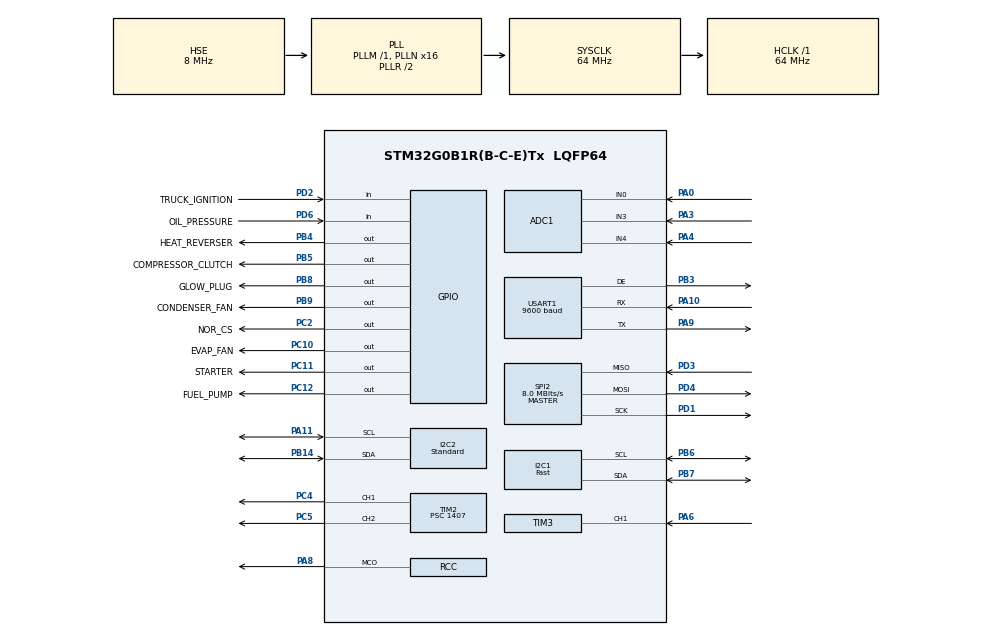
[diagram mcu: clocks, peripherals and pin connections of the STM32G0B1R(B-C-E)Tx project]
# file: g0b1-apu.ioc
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ADC1.ClockPrescaler=ADC_CLOCK_SYNC_PCLK_DIV4
ADC1.ContinuousConvMode=ENABLE
ADC1.DMAContinuousRequests=ENABLE
ADC1.NbrOfConversion=1
ADC1.NbrOfConversionFlag=0
ADC1.Overrun=ADC_OVR_DATA_OVERWRITTEN
ADC1.OversamplingMode=ENABLE
ADC1.Ratio=ADC_OVERSAMPLING_RATIO_16
ADC1.RightBitShift=ADC_RIGHTBITSHIFT_4
ADC1.SamplingTimeCommon1=ADC_SAMPLETIME_160CYCLES_5
ADC1.SelectedChannel=ADC_CHANNEL_0|ADC_CHANNEL_3|ADC_CHANNEL_4
ADC1.Sequencer=NOT_FULLY_CONFIGURABLE
ADC1.master=1
Dma.ADC1.2.Direction=DMA_PERIPH_TO_MEMORY
Dma.ADC1.2.EventEnable=DISABLE
Dma.ADC1.2.Instance=DMA1_Channel3
Dma.ADC1.2.MemDataAlignment=DMA_MDATAALIGN_HALFWORD
Dma.ADC1.2.MemInc=DMA_MINC_ENABLE
Dma.ADC1.2.Mode=DMA_CIRCULAR
Dma.ADC1.2.PeriphDataAlignment=DMA_PDATAALIGN_HALFWORD
Dma.ADC1.2.PeriphInc=DMA_PINC_DISABLE
Dma.ADC1.2.Polarity=HAL_DMAMUX_REQ_GEN_RISING
Dma.ADC1.2.Priority=DMA_PRIORITY_LOW
Dma.ADC1.2.RequestNumber=1
Dma.ADC1.2.SignalID=NONE
Dma.ADC1.2.SyncEnable=DISABLE
Dma.ADC1.2.SyncPolarity=HAL_DMAMUX_SYNC_NO_EVENT
Dma.ADC1.2.SyncRequestNumber=1
Dma.ADC1.2.SyncSignalID=NONE
Dma.Request0=USART1_RX
Dma.Request1=USART1_TX
Dma.Request2=ADC1
Dma.USART1_RX.0.Direction=DMA_PERIPH_TO_MEMORY
Dma.USART1_RX.0.EventEnable=DISABLE
Dma.USART1_RX.0.Instance=DMA1_Channel1
Dma.USART1_RX.0.MemDataAlignment=DMA_MDATAALIGN_BYTE
Dma.USART1_RX.0.MemInc=DMA_MINC_ENABLE
Dma.USART1_RX.0.Mode=DMA_NORMAL
Dma.USART1_RX.0.PeriphDataAlignment=DMA_PDATAALIGN_BYTE
Dma.USART1_RX.0.PeriphInc=DMA_PINC_DISABLE
Dma.USART1_RX.0.Polarity=HAL_DMAMUX_REQ_GEN_RISING
Dma.USART1_RX.0.Priority=DMA_PRIORITY_LOW
Dma.USART1_RX.0.RequestNumber=1
Dma.USART1_RX.0.SignalID=NONE
Dma.USART1_RX.0.SyncEnable=DISABLE
Dma.USART1_RX.0.SyncPolarity=HAL_DMAMUX_SYNC_NO_EVENT
Dma.USART1_RX.0.SyncRequestNumber=1
Dma.USART1_RX.0.SyncSignalID=NONE
Dma.USART1_TX.1.Direction=DMA_MEMORY_TO_PERIPH
Dma.USART1_TX.1.EventEnable=DISABLE
Dma.USART1_TX.1.Instance=DMA1_Channel2
Dma.USART1_TX.1.MemDataAlignment=DMA_MDATAALIGN_BYTE
Dma.USART1_TX.1.MemInc=DMA_MINC_ENABLE
Dma.USART1_TX.1.Mode=DMA_NORMAL
Dma.USART1_TX.1.PeriphDataAlignment=DMA_PDATAALIGN_BYTE
Dma.USART1_TX.1.PeriphInc=DMA_PINC_DISABLE
Dma.USART1_TX.1.Polarity=HAL_DMAMUX_REQ_GEN_RISING
Dma.USART1_TX.1.Priority=DMA_PRIORITY_LOW
Dma.USART1_TX.1.RequestNumber=1
Dma.USART1_TX.1.SignalID=NONE
Dma.USART1_TX.1.SyncEnable=DISABLE
Dma.USART1_TX.1.SyncPolarity=HAL_DMAMUX_SYNC_NO_EVENT
Dma.USART1_TX.1.SyncRequestNumber=1
Dma.USART1_TX.1.SyncSignalID=NONE
I2C1.AddressingMode=I2C_ADDRESSINGMODE_7BIT
I2C1.Analog_Filter=I2C_ANALOGFILTER_ENABLE
I2C1.CustomTiming=Disabled
I2C1.DualAddressMode=I2C_DUALADDRESS_DISABLE
I2C1.GeneralCallMode=I2C_GENERALCALL_DISABLE
I2C1.I2C_Coeff_DF=0x0
I2C1.I2C_Fall_Time=10
I2C1.I2C_Rise_Time=100
I2C1.I2C_Speed_Mode=I2C_Fast
I2C1.NoStretchMode=I2C_NOSTRETCH_DISABLE
I2C1.OwnAddress=0x0
I2C1.Speed=400
I2C1.Timing=0x00C0216C
I2C2.AddressingMode=I2C_ADDRESSINGMODE_7BIT
I2C2.Analog_Filter=I2C_ANALOGFILTER_ENABLE
I2C2.CustomTiming=Disabled
I2C2.DualAddressMode=I2C_DUALADDRESS_DISABLE
I2C2.GeneralCallMode=I2C_GENERALCALL_DISABLE
I2C2.I2C_Coeff_DF=0x0
I2C2.I2C_Fall_Time=10
I2C2.I2C_Rise_Time=100
I2C2.I2C_Speed_Mode=I2C_Standard
I2C2.NoStretchMode=I2C_NOSTRETCH_DISABLE
I2C2.OwnAddress=0x0
I2C2.Speed=50
I2C2.Timing=0xF0102527
IWDG.Prescaler=IWDG_PRESCALER_32
IWDG.Reload=1999
Mcu.Family=STM32G0
Mcu.Name=STM32G0B1R(B-C-E)Tx
Mcu.Package=LQFP64
NVIC.DMA1_Channel1_IRQn=true\:0\:0\:false\:false\:true\:false\:true\:true
NVIC.DMA1_Channel2_3_IRQn=true\:0\:0\:false\:false\:true\:false\:true\:true
NVIC.TIM3_TIM4_IRQn=true\:0\:0\:false\:false\:true\:true\:true\:true
NVIC.USART1_IRQn=true\:0\:0\:false\:false\:true\:true\:true\:true
PA0.Mode=IN0
PA0.Signal=ADC1_IN0
PA10.Mode=Asynchronous
PA10.Signal=USART1_RX
PA11\ [PA9].Mode=I2C
PA11\ [PA9].Signal=I2C2_SCL
PA13.Mode=Serial_Wire
PA13.Signal=SYS_SWDIO
PA14-BOOT0.Mode=Serial_Wire
PA14-BOOT0.Signal=SYS_SWCLK
PA3.Mode=IN3
PA3.Signal=ADC1_IN3
PA4.Mode=IN4
PA4.Signal=ADC1_IN4
PA6.Signal=S_TIM3_CH1
PA8.Mode=Clock-out
PA8.Signal=RCC_MCO
PA9.Mode=Asynchronous
PA9.Signal=USART1_TX
PB14.Mode=I2C
PB14.Signal=I2C2_SDA
PB3.Mode=Hardware Flow Control (RS485)
PB3.Signal=USART1_DE
PB4.GPIO_Label=HEAT_REVERSER
PB4.Signal=GPIO_Output
PB5.GPIO_Label=COMPRESSOR_CLUTCH
PB5.Signal=GPIO_Output
PB6.Mode=I2C
PB6.Signal=I2C1_SCL
PB7.Mode=I2C
PB7.Signal=I2C1_SDA
PB8.GPIO_Label=GLOW_PLUG
PB8.Signal=GPIO_Output
PB9.GPIO_Label=CONDENSER_FAN
PB9.Signal=GPIO_Output
PC10.GPIO_Label=EVAP_FAN
PC10.Signal=GPIO_Output
PC11.GPIO_Label=STARTER
PC11.Signal=GPIO_Output
PC12.GPIO_Label=FUEL_PUMP
PC12.Signal=GPIO_Output
PC2.GPIO_Label=NOR_CS
PC2.PinState=GPIO_PIN_SET
PC2.Signal=GPIO_Output
PC4.Signal=S_TIM2_CH1_ETR
PC5.Signal=S_TIM2_CH2
PD1.Mode=Full_Duplex_Master
PD1.Signal=SPI2_SCK
PD2.GPIO_Label=TRUCK_IGNITION
PD2.GPIO_PuPd=GPIO_PULLUP
PD2.Signal=GPIO_Input
PD3.Mode=Full_Duplex_Master
PD3.Signal=SPI2_MISO
PD4.Mode=Full_Duplex_Master
PD4.Signal=SPI2_MOSI
PD6.GPIO_Label=OIL_PRESSURE
PD6.GPIO_PuPd=GPIO_PULLUP
PD6.Signal=GPIO_Input
PF0-OSC_IN\ (PF0).Mode=HSE-External-Oscillator
PF0-OSC_IN\ (PF0).Signal=RCC_OSC_IN
PF1-OSC_OUT\ (PF1).Mode=HSE-External-Oscillator
PF1-OSC_OUT\ (PF1).Signal=RCC_OSC_OUT
ProjectManager.HeapSize=0x200
ProjectManager.StackSize=0x400
ProjectManager.TargetToolchain=STM32CubeIDE
RCC.ADCFreq_Value=64000000
RCC.AHBFreq_Value=64000000
RCC.CortexFreq_Value=64000000
RCC.EXTERNAL_CLOCK_VALUE=48000
RCC.HCLKFreq_Value=64000000
RCC.HSE_VALUE=8000000
RCC.HSI48_VALUE=48000000
RCC.HSI_VALUE=16000000
RCC.LSE_VALUE=32768
RCC.PLLN=16
RCC.PLLP=RCC_PLLP_DIV4
RCC.PLLSourceVirtual=RCC_PLLSOURCE_HSE
RCC.RCC_MCODiv=RCC_MCODIV_16
RCC.SYSCLKFreq_VALUE=64000000
RCC.SYSCLKSource=RCC_SYSCLKSOURCE_PLLCLK
RCC.USBFreq_Value=48000000
RCC.VCOOutputFreq_Value=128000000
SH.S_TIM2_CH1_ETR.0=TIM2_CH1,PWM Generation1 CH1
SH.S_TIM2_CH2.0=TIM2_CH2,PWM Generation2 CH2
SH.S_TIM3_CH1.0=TIM3_CH1,Input_Capture1_from_TI1
SPI2.BaudRatePrescaler=SPI_BAUDRATEPRESCALER_8
SPI2.CLKPhase=SPI_PHASE_1EDGE
SPI2.CLKPolarity=SPI_POLARITY_LOW
SPI2.CalculateBaudRate=8.0 MBits/s
SPI2.DataSize=SPI_DATASIZE_8BIT
SPI2.Direction=SPI_DIRECTION_2LINES
SPI2.FirstBit=SPI_FIRSTBIT_MSB
SPI2.Mode=SPI_MODE_MASTER
SPI2.NSS=SPI_NSS_SOFT
SPI2.VirtualType=VM_MASTER
TIM2.AutoReloadPreload=TIM_AUTORELOAD_PRELOAD_ENABLE
TIM2.Channel-PWM\ Generation1\ CH1=TIM_CHANNEL_1
TIM2.Channel-PWM\ Generation2\ CH2=TIM_CHANNEL_2
TIM2.Period=999
TIM2.Prescaler=1407
TIM2.Pulse-PWM\ Generation1\ CH1=0
TIM2.Pulse-PWM\ Generation2\ CH2=0
TIM3.Channel-Input_Capture1_from_TI1=TIM_CHANNEL_1
TIM3.ICFilter_CH1=12
TIM3.Prescaler=127
USART1.BaudRate=9600
USART1.VirtualMode-Asynchronous=VM_ASYNC
USART1.VirtualMode-Hardware\ Flow\ Control\ (RS485)=VM_ASYNC
VP_IWDG_VS_IWDG.Mode=IWDG_Activate
VP_SYS_VS_DBSignals.Mode=DisableDeadBatterySignals
VP_TIM3_VS_ClockSourceINT.Mode=Internal
board=custom

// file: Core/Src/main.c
/* USER CODE BEGIN Header */
/**
  ******************************************************************************
  * @file           : main.c
  * @brief          : Main program body
  ******************************************************************************
  * @attention
  *
  * Copyright (c) 2026 STMicroelectronics.
  * All rights reserved.
  *
  * This software is licensed under terms that can be found in the LICENSE file
  * in the root directory of this software component.
  * If no LICENSE file comes with this software, it is provided AS-IS.
  *
  ******************************************************************************
  */
/* USER CODE END Header */
#include "main.h"

/* USER CODE BEGIN Includes */
#include "app_main.h"
/* USER CODE END Includes */

ADC_HandleTypeDef hadc1;
DMA_HandleTypeDef hdma_adc1;

I2C_HandleTypeDef hi2c1;
I2C_HandleTypeDef hi2c2;

IWDG_HandleTypeDef hiwdg;

SPI_HandleTypeDef hspi2;

TIM_HandleTypeDef htim2;
TIM_HandleTypeDef htim3;

UART_HandleTypeDef huart1;
DMA_HandleTypeDef hdma_usart1_rx;
DMA_HandleTypeDef hdma_usart1_tx;

void SystemClock_Config(void);
static void MX_GPIO_Init(void);
static void MX_DMA_Init(void);
static void MX_TIM2_Init(void);
static void MX_USART1_UART_Init(void);
static void MX_SPI2_Init(void);
static void MX_I2C1_Init(void);
static void MX_ADC1_Init(void);
static void MX_TIM3_Init(void);
static void MX_I2C2_Init(void);
static void MX_IWDG_Init(void);

int main(void)
{

  /* MCU Configuration--------------------------------------------------------*/

  /* Reset of all peripherals, Initializes the Flash interface and the Systick. */
  HAL_Init();

  /* Configure the system clock */
  SystemClock_Config();

  /* Initialize all configured peripherals */
  MX_GPIO_Init();
  MX_DMA_Init();
  MX_TIM2_Init();
  MX_USART1_UART_Init();
  MX_SPI2_Init();
  MX_I2C1_Init();
  MX_ADC1_Init();
  MX_TIM3_Init();
  MX_I2C2_Init();
  MX_IWDG_Init();
  /* USER CODE BEGIN 2 */
  app_main();   /* never returns — owns the superloop (Task 1: idle; MCO on PA8 = 4 MHz validates the clock) */
  /* USER CODE END 2 */

  /* Infinite loop */
  while (1)
  {

  }
}

void SystemClock_Config(void)
{
  RCC_OscInitTypeDef RCC_OscInitStruct = {0};
  RCC_ClkInitTypeDef RCC_ClkInitStruct = {0};

  /** Configure the main internal regulator output voltage
  */
  HAL_PWREx_ControlVoltageScaling(PWR_REGULATOR_VOLTAGE_SCALE1);

  /** Initializes the RCC Oscillators according to the specified parameters
  * in the RCC_OscInitTypeDef structure.
  */
  RCC_OscInitStruct.OscillatorType = RCC_OSCILLATORTYPE_LSI|RCC_OSCILLATORTYPE_HSE;
  RCC_OscInitStruct.HSEState = RCC_HSE_ON;
  RCC_OscInitStruct.LSIState = RCC_LSI_ON;
  RCC_OscInitStruct.PLL.PLLState = RCC_PLL_ON;
  RCC_OscInitStruct.PLL.PLLSource = RCC_PLLSOURCE_HSE;
  RCC_OscInitStruct.PLL.PLLM = RCC_PLLM_DIV1;
  RCC_OscInitStruct.PLL.PLLN = 16;
  RCC_OscInitStruct.PLL.PLLP = RCC_PLLP_DIV4;
  RCC_OscInitStruct.PLL.PLLQ = RCC_PLLQ_DIV2;
  RCC_OscInitStruct.PLL.PLLR = RCC_PLLR_DIV2;
  if (HAL_RCC_OscConfig(&RCC_OscInitStruct) != HAL_OK)
  {
    Error_Handler();
  }

  /** Initializes the CPU, AHB and APB buses clocks
  */
  RCC_ClkInitStruct.ClockType = RCC_CLOCKTYPE_HCLK|RCC_CLOCKTYPE_SYSCLK
                              |RCC_CLOCKTYPE_PCLK1;
  RCC_ClkInitStruct.SYSCLKSource = RCC_SYSCLKSOURCE_PLLCLK;
  RCC_ClkInitStruct.AHBCLKDivider = RCC_SYSCLK_DIV1;
  RCC_ClkInitStruct.APB1CLKDivider = RCC_HCLK_DIV1;

  if (HAL_RCC_ClockConfig(&RCC_ClkInitStruct, FLASH_LATENCY_2) != HAL_OK)
  {
    Error_Handler();
  }
  HAL_RCC_MCOConfig(RCC_MCO1, RCC_MCO1SOURCE_SYSCLK, RCC_MCODIV_16);
}

static void MX_ADC1_Init(void)
{

  ADC_ChannelConfTypeDef sConfig = {0};

  /** Configure the global features of the ADC (Clock, Resolution, Data Alignment and number of conversion)
  */
  hadc1.Instance = ADC1;
  hadc1.Init.ClockPrescaler = ADC_CLOCK_SYNC_PCLK_DIV4;
  hadc1.Init.Resolution = ADC_RESOLUTION_12B;
  hadc1.Init.DataAlign = ADC_DATAALIGN_RIGHT;
  hadc1.Init.ScanConvMode = ADC_SCAN_SEQ_FIXED;
  hadc1.Init.EOCSelection = ADC_EOC_SINGLE_CONV;
  hadc1.Init.LowPowerAutoWait = DISABLE;
  hadc1.Init.LowPowerAutoPowerOff = DISABLE;
  hadc1.Init.ContinuousConvMode = ENABLE;
  hadc1.Init.NbrOfConversion = 1;
  hadc1.Init.ExternalTrigConv = ADC_SOFTWARE_START;
  hadc1.Init.ExternalTrigConvEdge = ADC_EXTERNALTRIGCONVEDGE_NONE;
  hadc1.Init.DMAContinuousRequests = ENABLE;
  hadc1.Init.Overrun = ADC_OVR_DATA_OVERWRITTEN;
  hadc1.Init.SamplingTimeCommon1 = ADC_SAMPLETIME_160CYCLES_5;
  hadc1.Init.OversamplingMode = ENABLE;
  hadc1.Init.Oversampling.Ratio = ADC_OVERSAMPLING_RATIO_16;
  hadc1.Init.Oversampling.RightBitShift = ADC_RIGHTBITSHIFT_4;
  hadc1.Init.Oversampling.TriggeredMode = ADC_TRIGGEREDMODE_SINGLE_TRIGGER;
  hadc1.Init.TriggerFrequencyMode = ADC_TRIGGER_FREQ_HIGH;
  if (HAL_ADC_Init(&hadc1) != HAL_OK)
  {
    Error_Handler();
  }

  /** Configure Regular Channel
  */
  sConfig.Channel = ADC_CHANNEL_0;
  sConfig.Rank = ADC_RANK_CHANNEL_NUMBER;
  if (HAL_ADC_ConfigChannel(&hadc1, &sConfig) != HAL_OK)
  {
    Error_Handler();
  }

  /** Configure Regular Channel
  */
  sConfig.Channel = ADC_CHANNEL_3;
  if (HAL_ADC_ConfigChannel(&hadc1, &sConfig) != HAL_OK)
  {
    Error_Handler();
  }

  /** Configure Regular Channel
  */
  sConfig.Channel = ADC_CHANNEL_4;
  if (HAL_ADC_ConfigChannel(&hadc1, &sConfig) != HAL_OK)
  {
    Error_Handler();
  }

}

static void MX_I2C1_Init(void)
{

  hi2c1.Instance = I2C1;
  hi2c1.Init.Timing = 0x00C0216C;
  hi2c1.Init.OwnAddress1 = 0;
  hi2c1.Init.AddressingMode = I2C_ADDRESSINGMODE_7BIT;
  hi2c1.Init.DualAddressMode = I2C_DUALADDRESS_DISABLE;
  hi2c1.Init.OwnAddress2 = 0;
  hi2c1.Init.OwnAddress2Masks = I2C_OA2_NOMASK;
  hi2c1.Init.GeneralCallMode = I2C_GENERALCALL_DISABLE;
  hi2c1.Init.NoStretchMode = I2C_NOSTRETCH_DISABLE;
  if (HAL_I2C_Init(&hi2c1) != HAL_OK)
  {
    Error_Handler();
  }

  /** Configure Analogue filter
  */
  if (HAL_I2CEx_ConfigAnalogFilter(&hi2c1, I2C_ANALOGFILTER_ENABLE) != HAL_OK)
  {
    Error_Handler();
  }

  /** Configure Digital filter
  */
  if (HAL_I2CEx_ConfigDigitalFilter(&hi2c1, 0x0) != HAL_OK)
  {
    Error_Handler();
  }

}

static void MX_I2C2_Init(void)
{

  hi2c2.Instance = I2C2;
  hi2c2.Init.Timing = 0x60302730; /* 100 kHz standard mode at 64 MHz PCLK */
  hi2c2.Init.OwnAddress1 = 0;
  hi2c2.Init.AddressingMode = I2C_ADDRESSINGMODE_7BIT;
  hi2c2.Init.DualAddressMode = I2C_DUALADDRESS_DISABLE;
  hi2c2.Init.OwnAddress2 = 0;
  hi2c2.Init.OwnAddress2Masks = I2C_OA2_NOMASK;
  hi2c2.Init.GeneralCallMode = I2C_GENERALCALL_DISABLE;
  hi2c2.Init.NoStretchMode = I2C_NOSTRETCH_DISABLE;
  if (HAL_I2C_Init(&hi2c2) != HAL_OK)
  {
    Error_Handler();
  }

  /** Configure Analogue filter
  */
  if (HAL_I2CEx_ConfigAnalogFilter(&hi2c2, I2C_ANALOGFILTER_ENABLE) != HAL_OK)
  {
    Error_Handler();
  }

  /** Configure Digital filter
  */
  if (HAL_I2CEx_ConfigDigitalFilter(&hi2c2, 0x0) != HAL_OK)
  {
    Error_Handler();
  }

}

static void MX_IWDG_Init(void)
{

  hiwdg.Instance = IWDG;
  hiwdg.Init.Prescaler = IWDG_PRESCALER_32;
  hiwdg.Init.Window = 4095;
  hiwdg.Init.Reload = 1999;
  if (HAL_IWDG_Init(&hiwdg) != HAL_OK)
  {
    Error_Handler();
  }

}

static void MX_SPI2_Init(void)
{

  /* SPI2 parameter configuration*/
  hspi2.Instance = SPI2;
  hspi2.Init.Mode = SPI_MODE_MASTER;
  hspi2.Init.Direction = SPI_DIRECTION_2LINES;
  hspi2.Init.DataSize = SPI_DATASIZE_8BIT;
  hspi2.Init.CLKPolarity = SPI_POLARITY_LOW;
  hspi2.Init.CLKPhase = SPI_PHASE_1EDGE;
  hspi2.Init.NSS = SPI_NSS_SOFT;
  hspi2.Init.BaudRatePrescaler = SPI_BAUDRATEPRESCALER_8;
  hspi2.Init.FirstBit = SPI_FIRSTBIT_MSB;
  hspi2.Init.TIMode = SPI_TIMODE_DISABLE;
  hspi2.Init.CRCCalculation = SPI_CRCCALCULATION_DISABLE;
  hspi2.Init.CRCPolynomial = 7;
  hspi2.Init.CRCLength = SPI_CRC_LENGTH_DATASIZE;
  hspi2.Init.NSSPMode = SPI_NSS_PULSE_ENABLE;
  if (HAL_SPI_Init(&hspi2) != HAL_OK)
  {
    Error_Handler();
  }

}

static void MX_TIM2_Init(void)
{

  TIM_MasterConfigTypeDef sMasterConfig = {0};
  TIM_OC_InitTypeDef sConfigOC = {0};

  htim2.Instance = TIM2;
  htim2.Init.Prescaler = 1407;
  htim2.Init.CounterMode = TIM_COUNTERMODE_UP;
  htim2.Init.Period = 999;
  htim2.Init.ClockDivision = TIM_CLOCKDIVISION_DIV1;
  htim2.Init.AutoReloadPreload = TIM_AUTORELOAD_PRELOAD_ENABLE;
  if (HAL_TIM_PWM_Init(&htim2) != HAL_OK)
  {
    Error_Handler();
  }
  sMasterConfig.MasterOutputTrigger = TIM_TRGO_RESET;
  sMasterConfig.MasterSlaveMode = TIM_MASTERSLAVEMODE_DISABLE;
  if (HAL_TIMEx_MasterConfigSynchronization(&htim2, &sMasterConfig) != HAL_OK)
  {
    Error_Handler();
  }
  sConfigOC.OCMode = TIM_OCMODE_PWM1;
  sConfigOC.Pulse = 0;
  sConfigOC.OCPolarity = TIM_OCPOLARITY_HIGH;
  sConfigOC.OCFastMode = TIM_OCFAST_DISABLE;
  if (HAL_TIM_PWM_ConfigChannel(&htim2, &sConfigOC, TIM_CHANNEL_1) != HAL_OK)
  {
    Error_Handler();
  }
  if (HAL_TIM_PWM_ConfigChannel(&htim2, &sConfigOC, TIM_CHANNEL_2) != HAL_OK)
  {
    Error_Handler();
  }
  HAL_TIM_MspPostInit(&htim2);

}

static void MX_TIM3_Init(void)
{

  TIM_ClockConfigTypeDef sClockSourceConfig = {0};
  TIM_MasterConfigTypeDef sMasterConfig = {0};
  TIM_IC_InitTypeDef sConfigIC = {0};

  htim3.Instance = TIM3;
  htim3.Init.Prescaler = 127;
  htim3.Init.CounterMode = TIM_COUNTERMODE_UP;
  htim3.Init.Period = 65535;
  htim3.Init.ClockDivision = TIM_CLOCKDIVISION_DIV1;
  htim3.Init.AutoReloadPreload = TIM_AUTORELOAD_PRELOAD_DISABLE;
  if (HAL_TIM_Base_Init(&htim3) != HAL_OK)
  {
    Error_Handler();
  }
  sClockSourceConfig.ClockSource = TIM_CLOCKSOURCE_INTERNAL;
  if (HAL_TIM_ConfigClockSource(&htim3, &sClockSourceConfig) != HAL_OK)
  {
    Error_Handler();
  }
  if (HAL_TIM_IC_Init(&htim3) != HAL_OK)
  {
    Error_Handler();
  }
  sMasterConfig.MasterOutputTrigger = TIM_TRGO_RESET;
  sMasterConfig.MasterSlaveMode = TIM_MASTERSLAVEMODE_DISABLE;
  if (HAL_TIMEx_MasterConfigSynchronization(&htim3, &sMasterConfig) != HAL_OK)
  {
    Error_Handler();
  }
  sConfigIC.ICPolarity = TIM_INPUTCHANNELPOLARITY_RISING;
  sConfigIC.ICSelection = TIM_ICSELECTION_DIRECTTI;
  sConfigIC.ICPrescaler = TIM_ICPSC_DIV1;
  sConfigIC.ICFilter = 12;   /* f_DTS/16, N=8 -> ~2us glitch reject on the tach edge; kills spurious-edge RPM bias/jitter. See docs/2026-09-15-rpm-tach-noise-fix.md. If CubeMX regenerates, set Channel1 Input Filter=12 in the GUI (.ioc TIM3.ICFilter_CH1) or this reverts to 0. */
  if (HAL_TIM_IC_ConfigChannel(&htim3, &sConfigIC, TIM_CHANNEL_1) != HAL_OK)
  {
    Error_Handler();
  }

}

static void MX_USART1_UART_Init(void)
{

  huart1.Instance = USART1;
  huart1.Init.BaudRate = 9600;
  huart1.Init.WordLength = UART_WORDLENGTH_8B;
  huart1.Init.StopBits = UART_STOPBITS_1;
  huart1.Init.Parity = UART_PARITY_NONE;
  huart1.Init.Mode = UART_MODE_TX_RX;
  huart1.Init.HwFlowCtl = UART_HWCONTROL_NONE;
  huart1.Init.OverSampling = UART_OVERSAMPLING_16;
  huart1.Init.OneBitSampling = UART_ONE_BIT_SAMPLE_DISABLE;
  huart1.Init.ClockPrescaler = UART_PRESCALER_DIV1;
  huart1.AdvancedInit.AdvFeatureInit = UART_ADVFEATURE_NO_INIT;
  if (HAL_RS485Ex_Init(&huart1, UART_DE_POLARITY_HIGH, 0, 0) != HAL_OK)
  {
    Error_Handler();
  }
  if (HAL_UARTEx_SetTxFifoThreshold(&huart1, UART_TXFIFO_THRESHOLD_1_8) != HAL_OK)
  {
    Error_Handler();
  }
  if (HAL_UARTEx_SetRxFifoThreshold(&huart1, UART_RXFIFO_THRESHOLD_1_8) != HAL_OK)
  {
    Error_Handler();
  }
  if (HAL_UARTEx_DisableFifoMode(&huart1) != HAL_OK)
  {
    Error_Handler();
  }

}

static void MX_DMA_Init(void)
{

  /* DMA controller clock enable */
  __HAL_RCC_DMA1_CLK_ENABLE();

  /* DMA interrupt init */
  /* DMA1_Channel1_IRQn interrupt configuration */
  HAL_NVIC_SetPriority(DMA1_Channel1_IRQn, 0, 0);
  HAL_NVIC_EnableIRQ(DMA1_Channel1_IRQn);
  /* DMA1_Channel2_3_IRQn interrupt configuration */
  HAL_NVIC_SetPriority(DMA1_Channel2_3_IRQn, 0, 0);
  HAL_NVIC_EnableIRQ(DMA1_Channel2_3_IRQn);

}

static void MX_GPIO_Init(void)
{
  GPIO_InitTypeDef GPIO_InitStruct = {0};

  /* GPIO Ports Clock Enable */
  __HAL_RCC_GPIOC_CLK_ENABLE();
  __HAL_RCC_GPIOF_CLK_ENABLE();
  __HAL_RCC_GPIOA_CLK_ENABLE();
  __HAL_RCC_GPIOB_CLK_ENABLE();
  __HAL_RCC_GPIOD_CLK_ENABLE();

  /*Configure GPIO pin Output Level */
  HAL_GPIO_WritePin(GPIOC, STARTER_Pin|FUEL_PUMP_Pin|EVAP_FAN_Pin, GPIO_PIN_RESET);

  /*Configure GPIO pin Output Level */
  HAL_GPIO_WritePin(NOR_CS_GPIO_Port, NOR_CS_Pin, GPIO_PIN_SET);

  /*Configure GPIO pin Output Level */
  HAL_GPIO_WritePin(GPIOB, HEAT_REVERSER_Pin|COMPRESSOR_CLUTCH_Pin|GLOW_PLUG_Pin|CONDENSER_FAN_Pin, GPIO_PIN_RESET);

  /*Configure GPIO pins : STARTER_Pin FUEL_PUMP_Pin NOR_CS_Pin EVAP_FAN_Pin */
  GPIO_InitStruct.Pin = STARTER_Pin|FUEL_PUMP_Pin|NOR_CS_Pin|EVAP_FAN_Pin;
  GPIO_InitStruct.Mode = GPIO_MODE_OUTPUT_PP;
  GPIO_InitStruct.Pull = GPIO_NOPULL;
  GPIO_InitStruct.Speed = GPIO_SPEED_FREQ_LOW;
  HAL_GPIO_Init(GPIOC, &GPIO_InitStruct);

  /*Configure GPIO pin : PA8 */
  GPIO_InitStruct.Pin = GPIO_PIN_8;
  GPIO_InitStruct.Mode = GPIO_MODE_AF_PP;
  GPIO_InitStruct.Pull = GPIO_NOPULL;
  GPIO_InitStruct.Speed = GPIO_SPEED_FREQ_LOW;
  GPIO_InitStruct.Alternate = GPIO_AF0_MCO;
  HAL_GPIO_Init(GPIOA, &GPIO_InitStruct);

  /*Configure GPIO pins : TRUCK_IGNITION_Pin OIL_PRESSURE_Pin */
  GPIO_InitStruct.Pin = TRUCK_IGNITION_Pin|OIL_PRESSURE_Pin;
  GPIO_InitStruct.Mode = GPIO_MODE_INPUT;
  GPIO_InitStruct.Pull = GPIO_PULLUP;
  HAL_GPIO_Init(GPIOD, &GPIO_InitStruct);

  /*Configure GPIO pins : HEAT_REVERSER_Pin COMPRESSOR_CLUTCH_Pin GLOW_PLUG_Pin CONDENSER_FAN_Pin */
  GPIO_InitStruct.Pin = HEAT_REVERSER_Pin|COMPRESSOR_CLUTCH_Pin|GLOW_PLUG_Pin|CONDENSER_FAN_Pin;
  GPIO_InitStruct.Mode = GPIO_MODE_OUTPUT_PP;
  GPIO_InitStruct.Pull = GPIO_NOPULL;
  GPIO_InitStruct.Speed = GPIO_SPEED_FREQ_LOW;
  HAL_GPIO_Init(GPIOB, &GPIO_InitStruct);

}

void Error_Handler(void)
{
  __disable_irq();
  while (1)
  {
  }
}
